# STM32F469AEH6 register map
File version: 1.0
Registers are 32-bit, access not given, reset 0x0 unless marked. A register's access mark holds for its fields unless they carry their own. Offsets are from the block's base; [hi:lo] are bit positions; {n}, {i} and the like mark numbered series; 'fields as' and 'values as' point back to an identical list.

## SYSCFG
Base 0x40013800
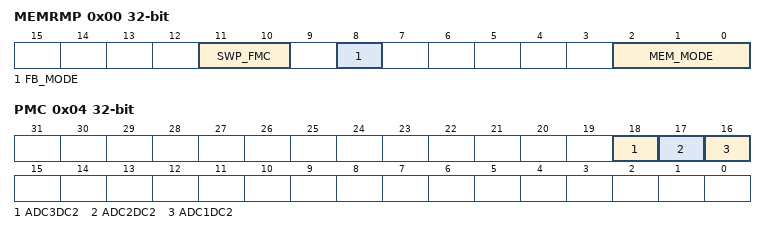
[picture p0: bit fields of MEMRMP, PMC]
0x00 MEMRMP
  [11:10] SWP_FMC, [8] FB_MODE, [2:0] MEM_MODE
0x04 PMC
  [18] ADC3DC2, [17] ADC2DC2, [16] ADC1DC2
{0x4+4i} EXTICR{i} (i=1..4)
0x20 CMPCR

## EXTI
Base 0x40013C00
0x00 IMR
0x04 EMR
0x08 RTSR
0x0C FTSR
0x10 SWIER
0x14 PR

## SAI1
Base 0x40015800
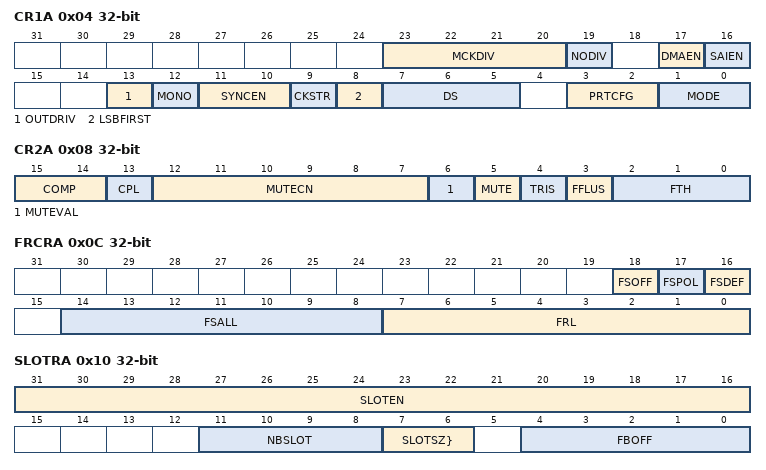
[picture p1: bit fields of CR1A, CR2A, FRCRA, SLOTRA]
0x04 CR1A
  [23:20] MCKDIV, [19] NODIV, [17] DMAEN, [16] SAIEN, [13] OUTDRIV, [12] MONO, [11:10] SYNCEN, [9] CKSTR, [8] LSBFIRST, [7:5] DS, [3:2] PRTCFG, [1:0] MODE
0x08 CR2A
  [15:14] COMP, [13] CPL, [12:7] MUTECN, [6] MUTEVAL, [5] MUTE, [4] TRIS, [3] FFLUS, [2:0] FTH
0x0C FRCRA
  [18] FSOFF, [17] FSPOL, [16] FSDEF, [14:8] FSALL, [7:0] FRL
0x10 SLOTRA
  [31:16] SLOTEN, [11:8] NBSLOT, [7:6] SLOTSZ}, [4:0] FBOFF
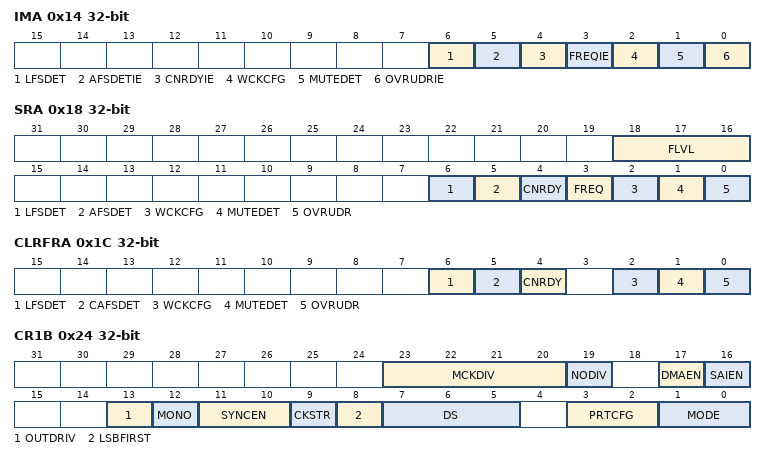
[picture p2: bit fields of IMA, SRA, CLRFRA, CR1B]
0x14 IMA
  [6] LFSDET, [5] AFSDETIE, [4] CNRDYIE, [3] FREQIE, [2] WCKCFG, [1] MUTEDET, [0] OVRUDRIE
0x18 SRA
  [18:16] FLVL, [6] LFSDET, [5] AFSDET, [4] CNRDY, [3] FREQ, [2] WCKCFG, [1] MUTEDET, [0] OVRUDR
0x1C CLRFRA
  [6] LFSDET, [5] CAFSDET, [4] CNRDY, [2] WCKCFG, [1] MUTEDET, [0] OVRUDR
0x20 DRA
  [31:0] DATA
0x24 CR1B
  fields as CR1A
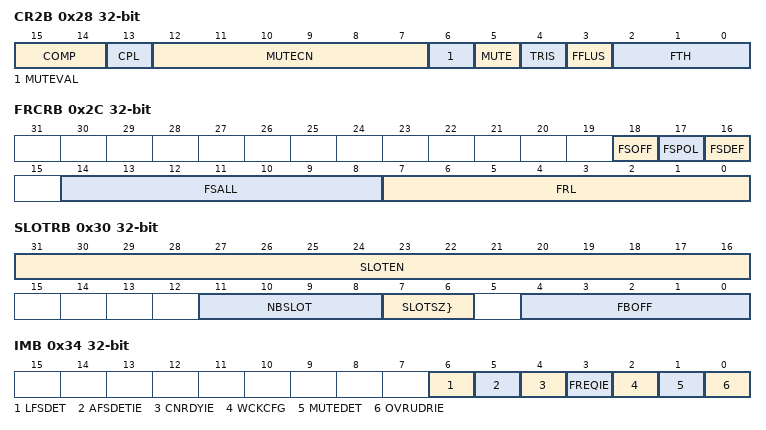
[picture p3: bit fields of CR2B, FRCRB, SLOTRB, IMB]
0x28 CR2B
  fields as CR2A
0x2C FRCRB
  [18] FSOFF, [17] FSPOL, [16] FSDEF, [14:8] FSALL, [7:0] FRL
0x30 SLOTRB
  [31:16] SLOTEN, [11:8] NBSLOT, [7:6] SLOTSZ}, [4:0] FBOFF
0x34 IMB
  fields as IMA
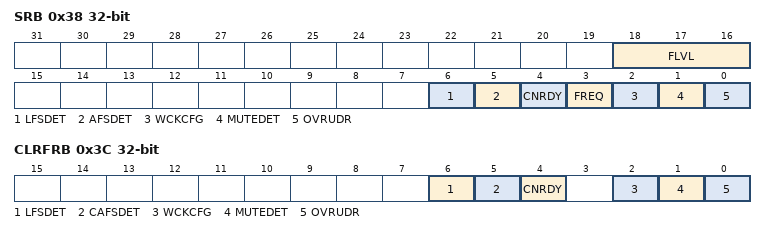
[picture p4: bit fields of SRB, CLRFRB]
0x38 SRB
  fields as SRA
0x3C CLRFRB
  fields as CLRFRA
0x40 DRB
  [31:0] DATA

## LTDC
Base 0x40016800
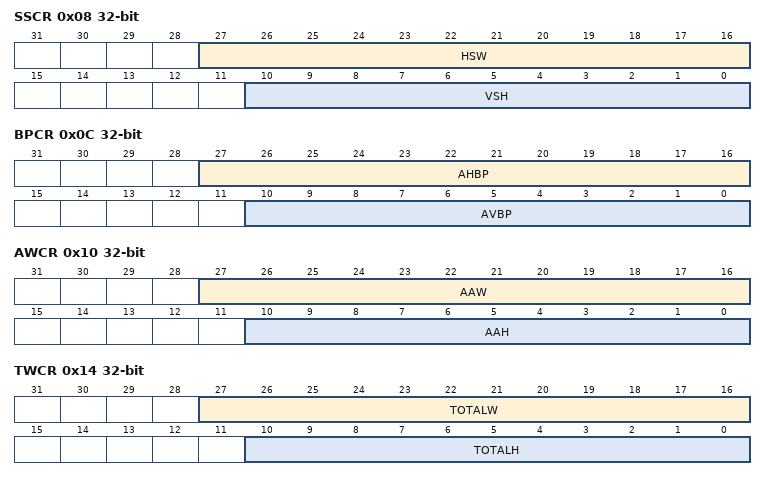
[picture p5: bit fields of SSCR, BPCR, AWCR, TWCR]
0x08 SSCR
  [27:16] HSW, [10:0] VSH
0x0C BPCR
  [27:16] AHBP, [10:0] AVBP
0x10 AWCR
  [27:16] AAW, [10:0] AAH
0x14 TWCR
  [27:16] TOTALW, [10:0] TOTALH
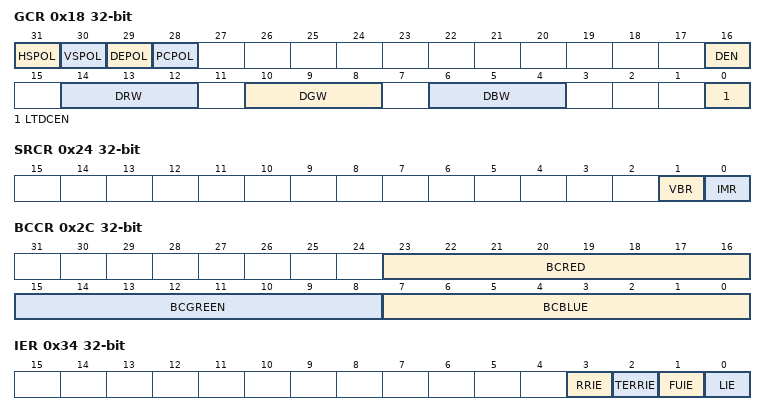
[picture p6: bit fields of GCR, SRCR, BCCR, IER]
0x18 GCR
  [31] HSPOL, [30] VSPOL, [29] DEPOL, [28] PCPOL, [16] DEN, [14:12] DRW, [10:8] DGW, [6:4] DBW, [0] LTDCEN
0x24 SRCR
  [1] VBR, [0] IMR
0x2C BCCR
  [23:16] BCRED, [15:8] BCGREEN, [7:0] BCBLUE
0x34 IER
  [3] RRIE, [2] TERRIE, [1] FUIE, [0] LIE
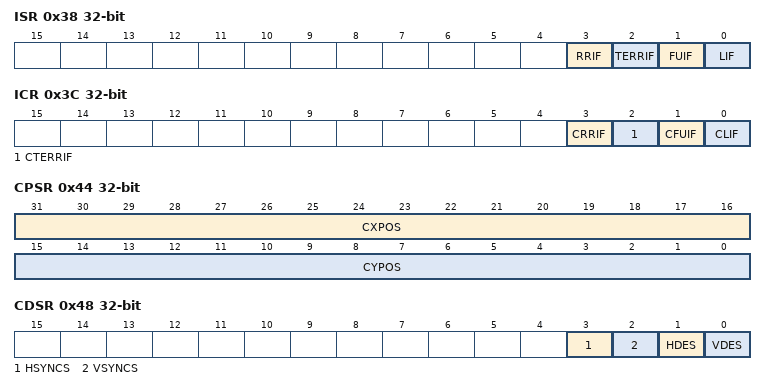
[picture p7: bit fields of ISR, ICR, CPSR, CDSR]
0x38 ISR
  [3] RRIF, [2] TERRIF, [1] FUIF, [0] LIF
0x3C ICR
  [3] CRRIF, [2] CTERRIF, [1] CFUIF, [0] CLIF
0x40 LIPCR
  [10:0] LIPOS
0x44 CPSR
  [31:16] CXPOS, [15:0] CYPOS
0x48 CDSR
  [3] HSYNCS, [2] VSYNCS, [1] HDES, [0] VDES
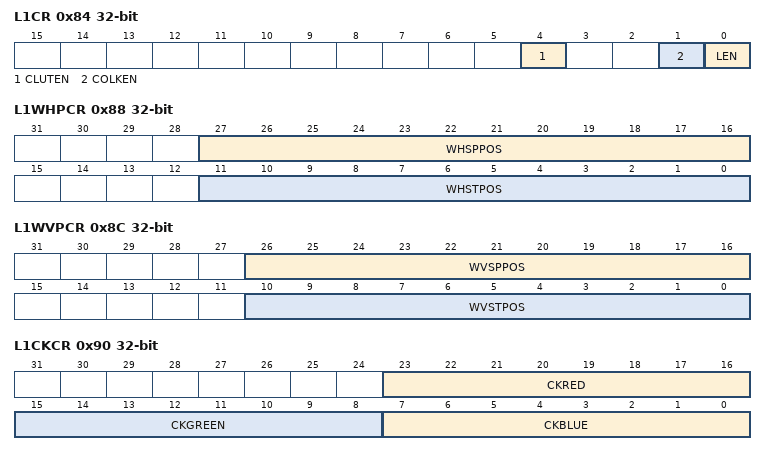
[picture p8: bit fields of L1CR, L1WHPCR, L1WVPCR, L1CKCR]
0x84 L1CR
  [4] CLUTEN, [1] COLKEN, [0] LEN
0x88 L1WHPCR
  [27:16] WHSPPOS, [11:0] WHSTPOS
0x8C L1WVPCR
  [26:16] WVSPPOS, [10:0] WVSTPOS
0x90 L1CKCR
  [23:16] CKRED, [15:8] CKGREEN, [7:0] CKBLUE
0x94 L1PFCR
  [2:0] PF
0x98 L1CACR
  [7:0] CONSTA
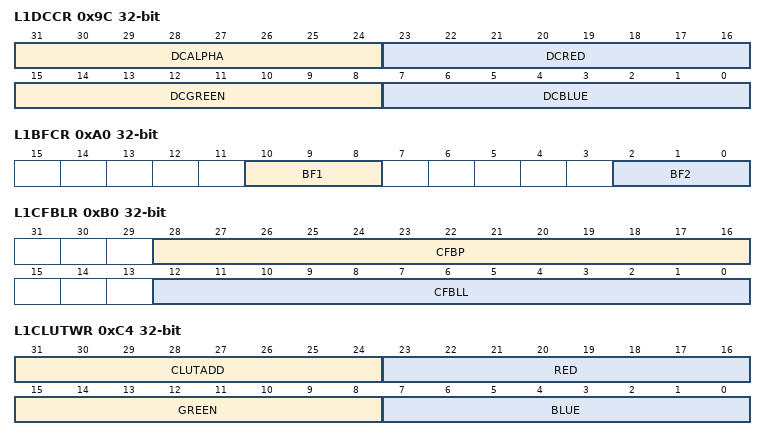
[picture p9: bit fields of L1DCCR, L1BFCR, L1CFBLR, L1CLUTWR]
0x9C L1DCCR
  [31:24] DCALPHA, [23:16] DCRED, [15:8] DCGREEN, [7:0] DCBLUE
0xA0 L1BFCR
  [10:8] BF1, [2:0] BF2
0xAC L1CFBAR
  [31:0] CFBADD
0xB0 L1CFBLR
  [28:16] CFBP, [12:0] CFBLL
0xB4 L1CFBLNR
  [10:0] CFBLNBR
0xC4 L1CLUTWR
  [31:24] CLUTADD, [23:16] RED, [15:8] GREEN, [7:0] BLUE
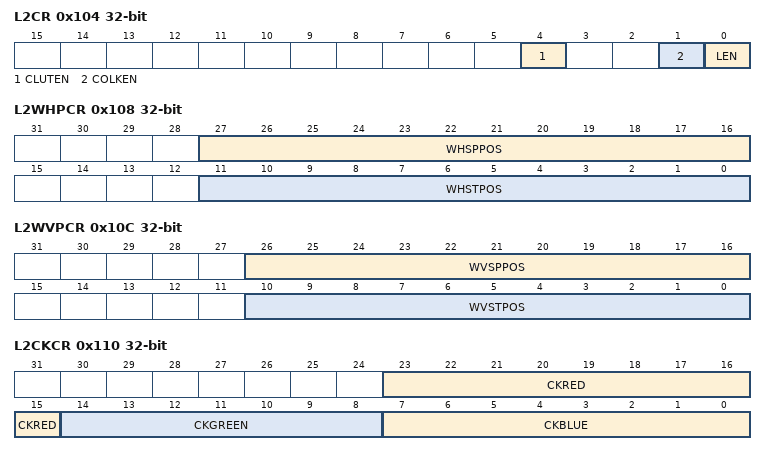
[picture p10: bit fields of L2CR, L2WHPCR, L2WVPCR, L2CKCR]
0x104 L2CR
  [4] CLUTEN, [1] COLKEN, [0] LEN
0x108 L2WHPCR
  [27:16] WHSPPOS, [11:0] WHSTPOS
0x10C L2WVPCR
  [26:16] WVSPPOS, [10:0] WVSTPOS
0x110 L2CKCR
  [23:15] CKRED, [14:8] CKGREEN, [7:0] CKBLUE
0x114 L2PFCR
  [2:0] PF
0x118 L2CACR
  [7:0] CONSTA
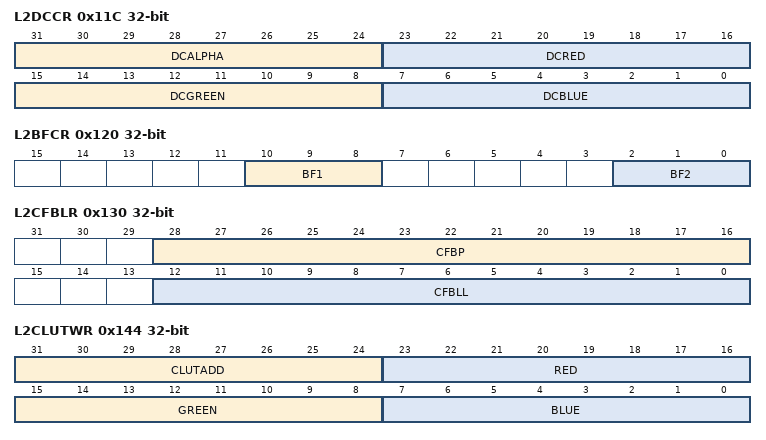
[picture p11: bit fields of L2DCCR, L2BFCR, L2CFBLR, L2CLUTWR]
0x11C L2DCCR
  [31:24] DCALPHA, [23:16] DCRED, [15:8] DCGREEN, [7:0] DCBLUE
0x120 L2BFCR
  [10:8] BF1, [2:0] BF2
0x12C L2CFBAR
  [31:0] CFBADD
0x130 L2CFBLR
  [28:16] CFBP, [12:0] CFBLL
0x134 L2CFBLNR
  [10:0] CFBLNBR
0x144 L2CLUTWR
  [31:24] CLUTADD, [23:16] RED, [15:8] GREEN, [7:0] BLUE

## GPIOA
Base 0x40020000
Same registers: GPIOB 0x40020400, GPIOC 0x40020800, GPIOD 0x40020C00, GPIOE 0x40021000, GPIOF 0x40021400, GPIOG 0x40021800, GPIOH 0x40021C00, GPIOI 0x40022000, GPIOJ 0x40022400, GPIOK 0x40022800
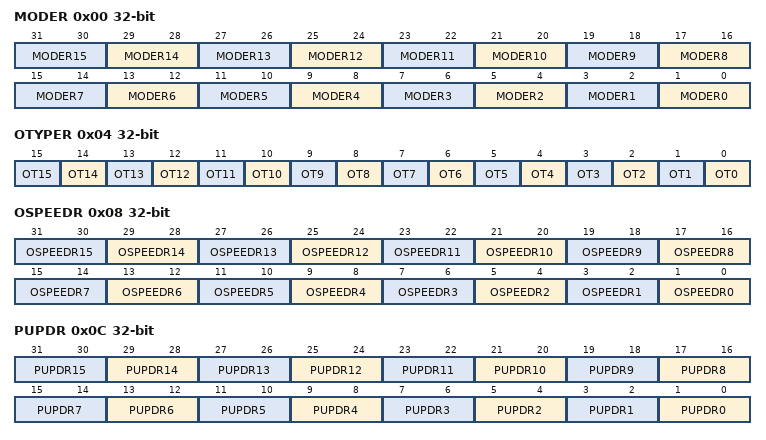
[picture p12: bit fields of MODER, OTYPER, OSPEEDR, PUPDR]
0x00 MODER
  [2n+1:2n] MODER{n} (n=0..15)
0x04 OTYPER
  [n] OT{n} (n=0..15)
0x08 OSPEEDR
  [2n+1:2n] OSPEEDR{n} (n=0..15)
0x0C PUPDR
  [2n+1:2n] PUPDR{n} (n=0..15)
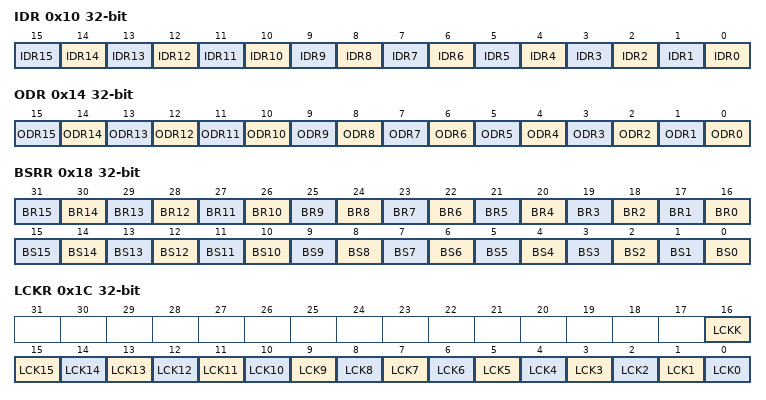
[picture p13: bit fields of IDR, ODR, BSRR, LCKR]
0x10 IDR
  [n] IDR{n} (n=0..15)
0x14 ODR
  [n] ODR{n} (n=0..15)
0x18 BSRR
  [n+16] BR{n} (n=0..15), [n] BS{n} (n=0..15)
0x1C LCKR
  [16] LCKK, [n] LCK{n} (n=0..15)
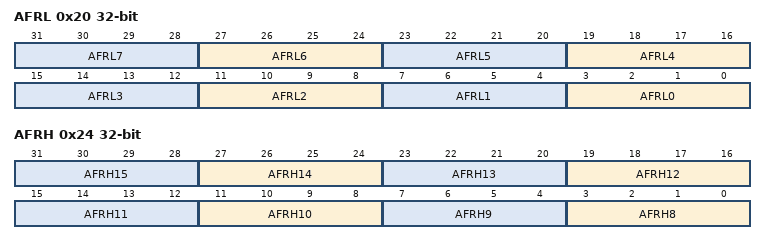
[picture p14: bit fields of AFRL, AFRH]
0x20 AFRL
  [4n+3:4n] AFRL{n} (n=0..7)
0x24 AFRH
  [4n-29:4n-32] AFRH{n} (n=8..15)
